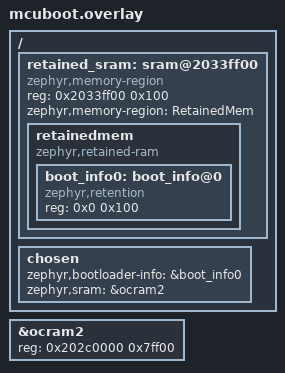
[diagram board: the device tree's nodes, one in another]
/* RT1170-EVK boot composition (MCUboot overlay). PROPOSED STARTING VALUES from the RT1170
 * design note "RT1170-EVK boot composition: memory-map choices": Inference, not adopted by the
 * owner, to be corrected by the first CI build. Nothing was built or run for this board. Mirrors
 * the RT1060-EVK Rev B file of the same name. Same retained-region node in MCUboot and application.
 * Unverified: that 0x2033ff00 is free of any other use in the application at v4.4.2. */
/ {
	retained_sram: sram@2033ff00 {
		compatible = "zephyr,memory-region", "mmio-sram";
		reg = <0x2033ff00 0x100>;
		ranges = <0x0 0x2033ff00 0x100>;
		zephyr,memory-region = "RetainedMem";
		status = "okay";
		#address-cells = <1>;
		#size-cells = <1>;

		retainedmem {
			compatible = "zephyr,retained-ram";
			status = "okay";
			ranges;
			#address-cells = <1>;
			#size-cells = <1>;

			boot_info0: boot_info@0 {
				compatible = "zephyr,retention";
				status = "okay";
				reg = <0x0 0x100>;
			};
		};
	};

	chosen {
		zephyr,bootloader-info = &boot_info0;
	};
};

/* Retained region must not be part of any image's RAM: trim OCRAM2 by 256 B in both images.
 * ocram2 is ocram@202c0000, 512 KiB (0x80000), in dts/arm/nxp/imxrt/nxp_rt1170.dtsi, so the
 * trimmed region ends at 0x2033ff00 where the retained region begins. The RT1060 overlay
 * redefines the node the same way. Unverified: that a reg override of this node is accepted
 * unchanged at v4.4.2. */
&ocram2 {
	reg = <0x202c0000 0x7ff00>;
};

/* MCUboot's own RAM is OCRAM2, as on the RT1060, because MCUboot loads the image into the SDRAM,
 * which is the board's default RAM. mcuboot.conf points the executable window back at the SDRAM. */
/ {
	chosen {
		zephyr,sram = &ocram2;
	};
};
